# STM32F427x register map
File version: 1.0
Registers are 32-bit, read-write, reset 0x0 unless marked. A register's access mark holds for its fields unless they carry their own. Offsets are from the block's base; [hi:lo] are bit positions; {n}, {i} and the like mark numbered series; 'fields as' and 'values as' point back to an identical list.

## FMC — Flexible memory controller
Base 0xA0000000
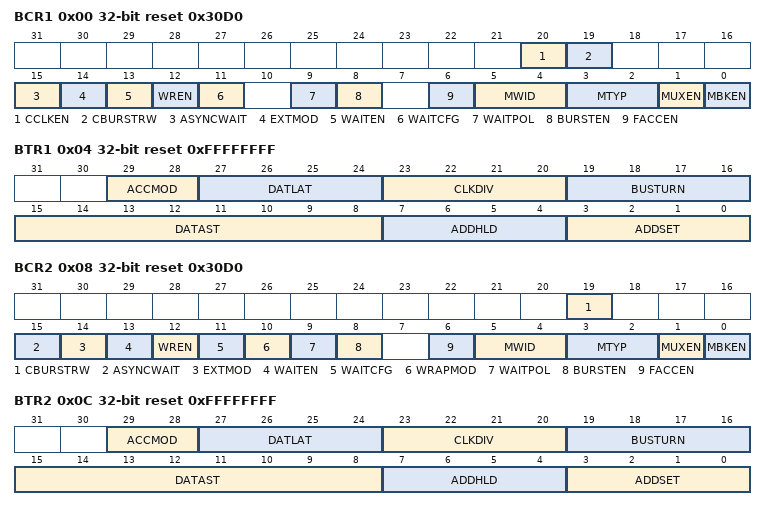
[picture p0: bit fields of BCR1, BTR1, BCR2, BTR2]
0x00 BCR1 reset 0x30D0 — SRAM/NOR-Flash chip-select control register 1
  [20] CCLKEN, [19] CBURSTRW, [15] ASYNCWAIT, [14] EXTMOD, [13] WAITEN, [12] WREN, [11] WAITCFG, [9] WAITPOL, [8] BURSTEN, [6] FACCEN, [5:4] MWID, [3:2] MTYP, [1] MUXEN, [0] MBKEN
0x04 BTR1 reset 0xFFFFFFFF — SRAM/NOR-Flash chip-select timing register 1
  [29:28] ACCMOD, [27:24] DATLAT, [23:20] CLKDIV, [19:16] BUSTURN, [15:8] DATAST, [7:4] ADDHLD, [3:0] ADDSET
0x08 BCR2 reset 0x30D0 — SRAM/NOR-Flash chip-select control register 2
  [19] CBURSTRW, [15] ASYNCWAIT, [14] EXTMOD, [13] WAITEN, [12] WREN, [11] WAITCFG, [10] WRAPMOD, [9] WAITPOL, [8] BURSTEN, [6] FACCEN, [5:4] MWID, [3:2] MTYP, [1] MUXEN, [0] MBKEN
0x0C BTR2 reset 0xFFFFFFFF — SRAM/NOR-Flash chip-select timing register 2
  fields as BTR1
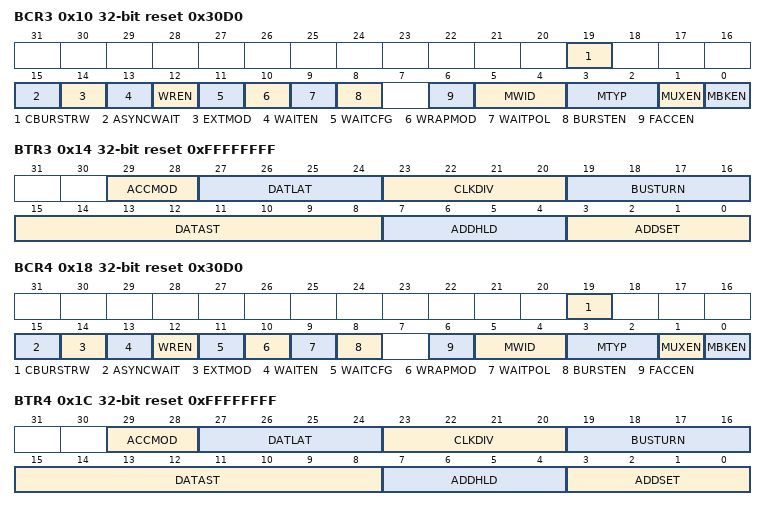
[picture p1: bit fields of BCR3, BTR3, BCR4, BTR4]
0x10 BCR3 reset 0x30D0 — SRAM/NOR-Flash chip-select control register 3
  fields as BCR2
0x14 BTR3 reset 0xFFFFFFFF — SRAM/NOR-Flash chip-select timing register 3
  fields as BTR1
0x18 BCR4 reset 0x30D0 — SRAM/NOR-Flash chip-select control register 4
  fields as BCR2
0x1C BTR4 reset 0xFFFFFFFF — SRAM/NOR-Flash chip-select timing register 4
  fields as BTR1
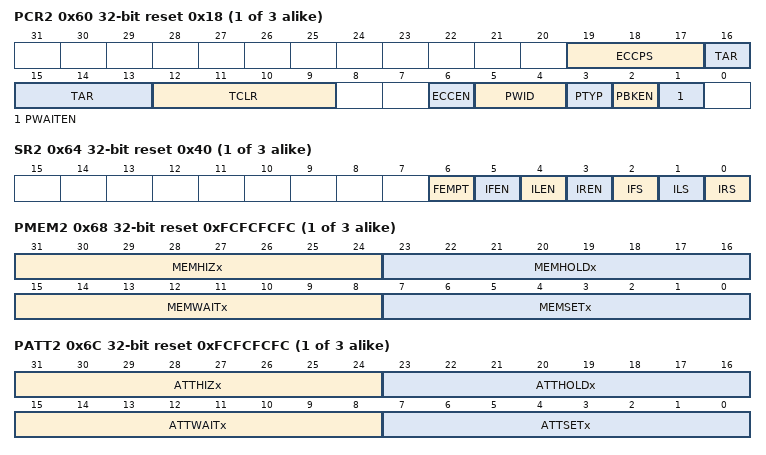
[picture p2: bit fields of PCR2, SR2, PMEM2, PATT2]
{0x20+0x20*i} PCR{i} reset 0x18 (i=2..4) — PC Card/NAND Flash control register {i}
  [19:17] ECCPS, [16:13] TAR, [12:9] TCLR, [6] ECCEN, [5:4] PWID, [3] PTYP, [2] PBKEN, [1] PWAITEN
{0x24+0x20*i} SR{i} access per field reset 0x40 (i=2..4) — FIFO status and interrupt register {i}
  [6] FEMPT ro, [5] IFEN rw, [4] ILEN rw, [3] IREN rw, [2] IFS rw, [1] ILS rw, [0] IRS rw
{0x28+0x20*i} PMEM{i} reset 0xFCFCFCFC (i=2..4) — Common memory space timing register {i}
  [31:24] MEMHIZx, [23:16] MEMHOLDx, [15:8] MEMWAITx, [7:0] MEMSETx
{0x2C+0x20*i} PATT{i} reset 0xFCFCFCFC (i=2..4) — Attribute memory space timing register {i}
  [31:24] ATTHIZx, [23:16] ATTHOLDx, [15:8] ATTWAITx, [7:0] ATTSETx
0x74 ECCR2 ro — ECC result register 2
  [31:0] ECCx
0x94 ECCR3 ro — ECC result register 3
  [31:0] ECCx
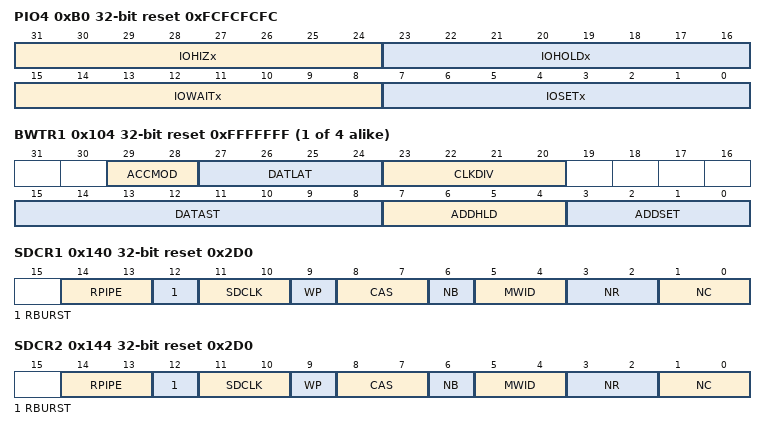
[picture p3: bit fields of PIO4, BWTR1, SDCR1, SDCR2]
0xB0 PIO4 reset 0xFCFCFCFC — I/O space timing register 4
  [31:24] IOHIZx, [23:16] IOHOLDx, [15:8] IOWAITx, [7:0] IOSETx
{0xFC+8i} BWTR{i} reset 0xFFFFFFF (i=1..4) — SRAM/NOR-Flash write timing registers {i}
  [29:28] ACCMOD, [27:24] DATLAT, [23:20] CLKDIV, [15:8] DATAST, [7:4] ADDHLD, [3:0] ADDSET
0x140 SDCR1 reset 0x2D0 — SDRAM Control Register 1
  [14:13] RPIPE — Read pipe
  [12] RBURST — Burst read
  [11:10] SDCLK — SDRAM clock configuration
  [9] WP — Write protection
  [8:7] CAS — CAS latency
  [6] NB — Number of internal banks
  [5:4] MWID — Memory data bus width
  [3:2] NR — Number of row address bits
  [1:0] NC — Number of column address bits
0x144 SDCR2 reset 0x2D0 — SDRAM Control Register 2
  fields as SDCR1
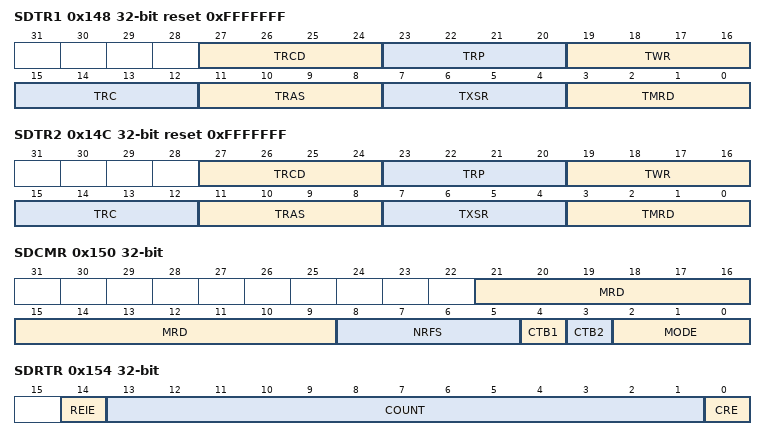
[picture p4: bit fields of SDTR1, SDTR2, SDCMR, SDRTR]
0x148 SDTR1 reset 0xFFFFFFF — SDRAM Timing register 1
  [27:24] TRCD — Row to column delay
  [23:20] TRP — Row precharge delay
  [19:16] TWR — Recovery delay
  [15:12] TRC — Row cycle delay
  [11:8] TRAS — Self refresh time
  [7:4] TXSR — Exit self-refresh delay
  [3:0] TMRD — Load Mode Register to Active
0x14C SDTR2 reset 0xFFFFFFF — SDRAM Timing register 2
  fields as SDTR1
0x150 SDCMR access per field — SDRAM Command Mode register
  [21:9] MRD rw — Mode Register definition
  [8:5] NRFS rw — Number of Auto-refresh
  [4] CTB1 wo — Command target bank 1
  [3] CTB2 wo — Command target bank 2
  [2:0] MODE wo — Command mode
0x154 SDRTR access per field — SDRAM Refresh Timer register
  [14] REIE rw — RES Interrupt Enable
  [13:1] COUNT rw — Refresh Timer Count
  [0] CRE wo — Clear Refresh error flag
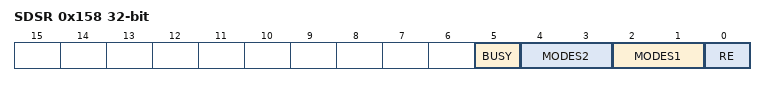
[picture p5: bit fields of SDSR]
0x158 SDSR ro — SDRAM Status register
  [5] BUSY — Busy status
  [4:3] MODES2 — Status Mode for Bank 2
  [2:1] MODES1 — Status Mode for Bank 1
  [0] RE — Refresh error flag

## I2C3 — Inter-integrated circuit
Base 0x40005C00
Same registers: I2C1 0x40005400, I2C2 0x40005800
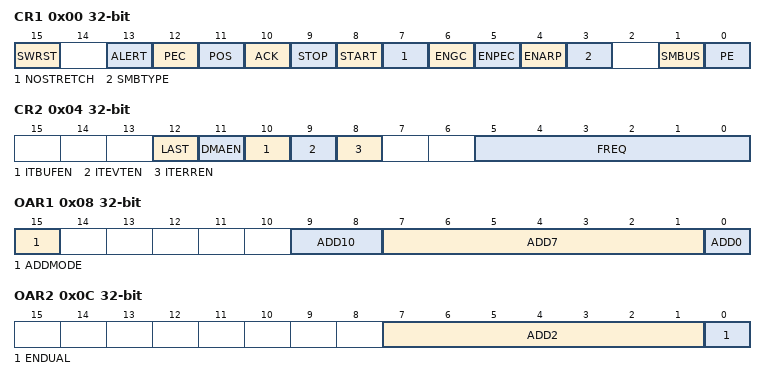
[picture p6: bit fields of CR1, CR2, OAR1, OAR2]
0x00 CR1 — Control register 1
  [15] SWRST — Software reset
  [13] ALERT — SMBus alert
  [12] PEC — Packet error checking
  [11] POS — Acknowledge/PEC Position (for data reception)
  [10] ACK — Acknowledge enable
  [9] STOP — Stop generation
  [8] START — Start generation
  [7] NOSTRETCH — Clock stretching disable (Slave mode)
  [6] ENGC — General call enable
  [5] ENPEC — PEC enable
  [4] ENARP — ARP enable
  [3] SMBTYPE — SMBus type
  [1] SMBUS — SMBus mode
  [0] PE — Peripheral enable
0x04 CR2 — Control register 2
  [12] LAST — DMA last transfer
  [11] DMAEN — DMA requests enable
  [10] ITBUFEN — Buffer interrupt enable
  [9] ITEVTEN — Event interrupt enable
  [8] ITERREN — Error interrupt enable
  [5:0] FREQ — Peripheral clock frequency
0x08 OAR1 — Own address register 1
  [15] ADDMODE — Addressing mode (slave mode)
  [9:8] ADD10 — Interface address
  [7:1] ADD7 — Interface address
  [0] ADD0 — Interface address
0x0C OAR2 — Own address register 2
  [7:1] ADD2 — Interface address
  [0] ENDUAL — Dual addressing mode enable
0x10 DR — Data register
  [7:0] DR — 8-bit data register
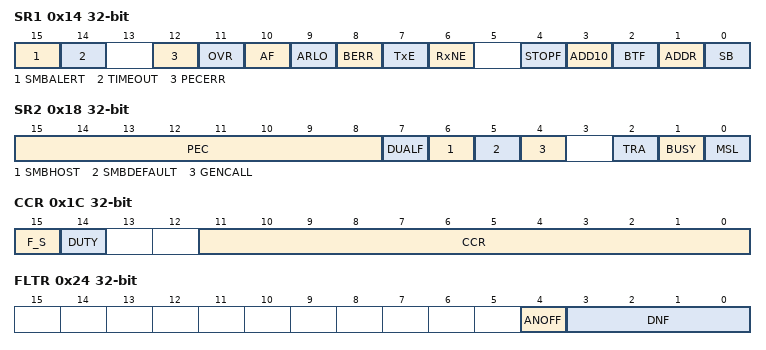
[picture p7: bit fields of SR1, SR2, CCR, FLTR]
0x14 SR1 access per field — Status register 1
  [15] SMBALERT rw — SMBus alert
  [14] TIMEOUT rw — Timeout or Tlow error
  [12] PECERR rw — PEC Error in reception
  [11] OVR rw — Overrun/Underrun
  [10] AF rw — Acknowledge failure
  [9] ARLO rw — Arbitration lost (master mode)
  [8] BERR rw — Bus error
  [7] TxE ro — Data register empty (transmitters)
  [6] RxNE ro — Data register not empty (receivers)
  [4] STOPF ro — Stop detection (slave mode)
  [3] ADD10 ro — 10-bit header sent (Master mode)
  [2] BTF ro — Byte transfer finished
  [1] ADDR ro — Address sent (master mode)/matched (slave mode)
  [0] SB ro — Start bit (Master mode)
0x18 SR2 ro — Status register 2
  [15:8] PEC — acket error checking register
  [7] DUALF — Dual flag (Slave mode)
  [6] SMBHOST — SMBus host header (Slave mode)
  [5] SMBDEFAULT — SMBus device default address (Slave mode)
  [4] GENCALL — General call address (Slave mode)
  [2] TRA — Transmitter/receiver
  [1] BUSY — Bus busy
  [0] MSL — Master/slave
0x1C CCR — Clock control register
  [15] F_S — I2C master mode selection
  [14] DUTY — Fast mode duty cycle
  [11:0] CCR — Clock control register in Fast/Standard mode (Master mode)
0x20 TRISE reset 0x2
  [5:0] TRISE — Maximum rise time in Fast/Standard mode (Master mode)
0x24 FLTR — I2C FLTR register
  [4] ANOFF — Analog noise filter OFF
  [3:0] DNF — Digital noise filter

## PWR — Power control
Base 0x40007000
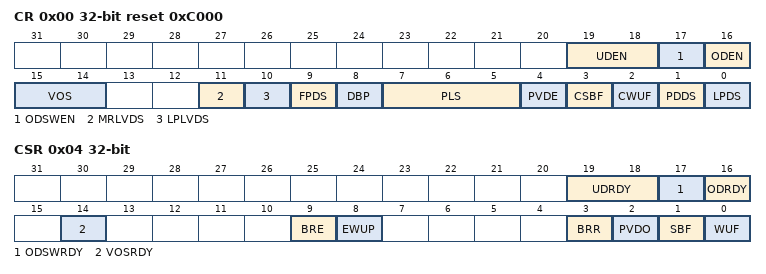
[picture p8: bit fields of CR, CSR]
0x00 CR reset 0xC000 — power control register
  [19:18] UDEN — Under-drive enable in stop mode
  [17] ODSWEN — Over-drive switching enabled
  [16] ODEN — Over-drive enable
  [15:14] VOS — Regulator voltage scaling output selection
  [11] MRLVDS — Main regulator low voltage in deepsleep mode
  [10] LPLVDS — Low-Power Regulator Low Voltage in deepsleep
  [9] FPDS — Flash power down in Stop mode
  [8] DBP — Disable backup domain write protection
  [7:5] PLS — PVD level selection
  [4] PVDE — Power voltage detector enable
  [3] CSBF — Clear standby flag
  [2] CWUF — Clear wakeup flag
  [1] PDDS — Power down deepsleep
  [0] LPDS — Low-power deep sleep
0x04 CSR access per field — power control/status register
  [19:18] UDRDY rw — Under-drive ready flag
  [17] ODSWRDY ro — Over-drive mode switching ready
  [16] ODRDY ro — Over-drive mode ready
  [14] VOSRDY rw — Regulator voltage scaling output selection ready bit
  [9] BRE rw — Backup regulator enable
  [8] EWUP rw — Enable WKUP pin
  [3] BRR ro — Backup regulator ready
  [2] PVDO ro — PVD output
  [1] SBF ro — Standby flag
  [0] WUF ro — Wakeup flag
